# STM32H503 register map
File version: 0.3
CPU: CM33 r0p0, little endian, MPU, FPU, 4 interrupt priority bits
Registers are 32-bit, read-write, reset 0x0 unless marked. A register's access mark holds for its fields unless they carry their own. Offsets are from the block's base; [hi:lo] are bit positions; {n}, {i} and the like mark numbered series.

## GPIOA — General-purpose I/Os
Base 0x42020000
Same registers: GPIOB 0x42020400, GPIOC 0x42020800, GPIOD 0x42020C00, GPIOH 0x42021C00
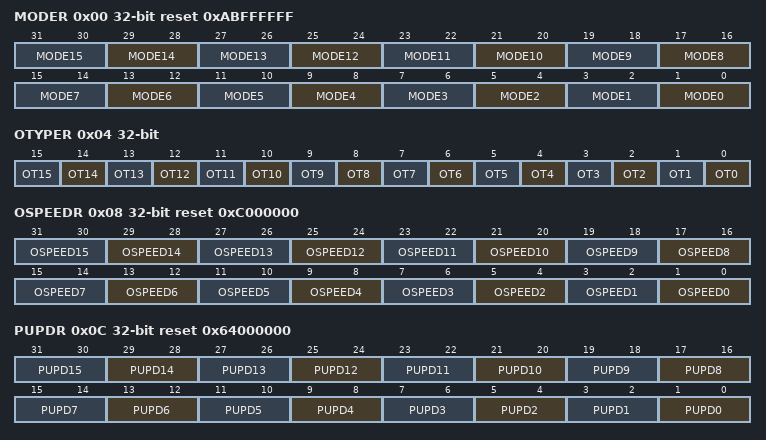
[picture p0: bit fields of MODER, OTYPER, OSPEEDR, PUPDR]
0x00 MODER reset 0xABFFFFFF — GPIO port mode register
  [2n+1:2n] MODE{n} (n=0..15) — Port x configuration I/O pin y (y = 15 to 0) These bits are written by software to configure the I/O mode. Note: The bitfield is reserved and must be kept to reset value when the corresponding I/O is not available on the selected package.
0x04 OTYPER — GPIO port output type register
  [n] OT{n} (n=0..15) — Port x configuration I/O pin y (y = 15 to 0) These bits are written by software to configure the I/O output type. Note: The bit is reserved and must be kept to reset value when the corresponding I/O is not available on the selected package.
0x08 OSPEEDR reset 0xC000000 — GPIO port output speed register
  [2n+1:2n] OSPEED{n} (n=0..15) — Port x configuration I/O pin y (y = 15 to 0) These bits are written by software to configure the I/O output speed. Note: Refer to the device datasheet for the frequency specifications and the power supply and load conditions for each speed. The bitfield is reserved and must be kept to reset value when the corresponding I/O is not available on the selected package.
0x0C PUPDR reset 0x64000000 — GPIO port pull-up/pull-down register
  [2n+1:2n] PUPD{n} (n=0..15) — Port x configuration I/O pin y (y = 15 to 0) These bits are written by software to configure the I/O pull-up or pull-down Note: The bitfield is reserved and must be kept to reset value when the corresponding I/O is not available on the selected package.
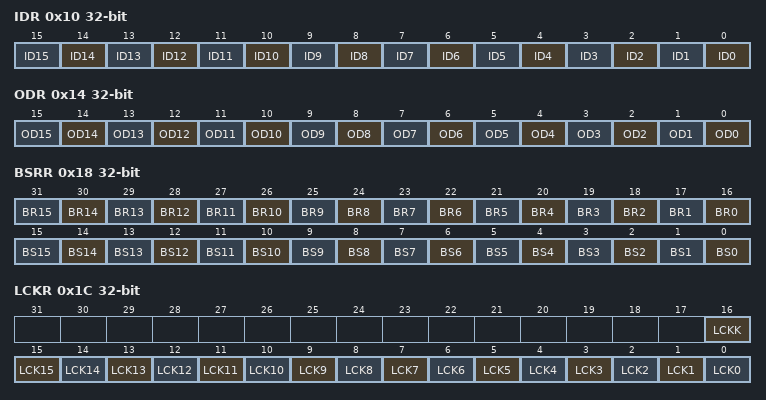
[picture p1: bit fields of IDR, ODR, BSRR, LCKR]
0x10 IDR ro (reset mask 0xFFFF0000) — GPIO port input data register
  [n] ID{n} (n=0..15) — Port x input data I/O pin y (y = 15 to 0) These bits are read-only. They contain the input value of the corresponding I/O port. Note: The bit is reserved and must be kept to reset value when the corresponding I/O is not available on the selected package.
0x14 ODR — GPIO port output data register
  [n] OD{n} (n=0..15) — Port output data I/O pin y (y = 15 to 0) These bits can be read and written by software. Note: For atomic bit set/reset, the OD bits can be individually set and/or reset by writing to the GPIOx_BSRR or GPIOx_BRR registers (x = A to D and H). The bit is reserved and must be kept to reset value when the corresponding I/O is not available on the selected package.
0x18 BSRR wo — GPIO port bit set/reset register
  [n+16] BR{n} (n=0..15) — Port x reset I/O pin y (y = 15 to 0) These bits are write-only. A read to these bits returns the value 0x0000. Note: If both BSy and BRy are set, BSy has priority. The bit is reserved and must be kept to reset value when the corresponding I/O is not available on the selected package.
  [n] BS{n} (n=0..15) — Port x set I/O pin y (y = 15 to 0) These bits are write-only. A read to these bits returns the value 0x0000. Note: The bit is reserved and must be kept to reset value when the corresponding I/O is not available on the selected package.
0x1C LCKR — GPIO port configuration lock register
  [16] LCKK — Lock key This bit can be read any time. It can only be modified using the lock key write sequence. - LOCK key write sequence: WR LCKR[16] = 1 + LCKR[15:0] WR LCKR[16] = 0 + LCKR[15:0] WR LCKR[16] = 1 + LCKR[15:0] - LOCK key read RD LCKR[16] = 1 (this read operation is optional but it confirms that the lock is active) Note: During the LOCK key write sequence, the value of LCK[15:0] must not change. Any error in the lock sequence aborts the LOCK. After the first LOCK sequence on any bit of the port, any read access on the LCKK bit returns 1 until the next MCU reset or peripheral reset.
  [n] LCK{n} (n=0..15) — Port x lock I/O pin y (y = 15 to 0) These bits are read/write but can only be written when the LCKK bit is 0 Note: The bit is reserved and must be kept to reset value when the corresponding I/O is not available on the selected package.
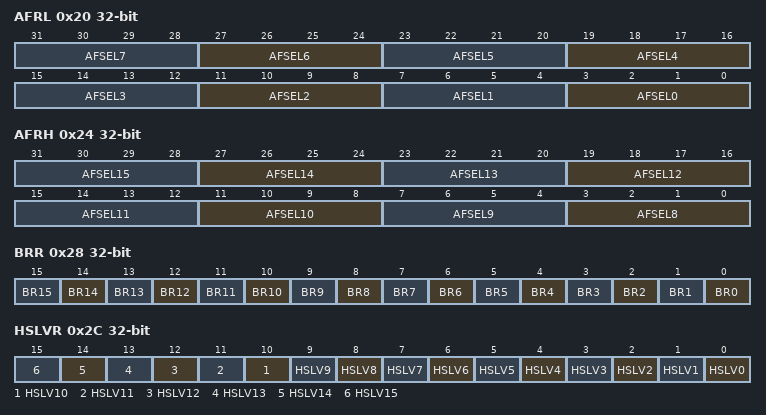
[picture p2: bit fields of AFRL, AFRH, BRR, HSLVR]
0x20 AFRL — GPIO alternate function low register
  [4n+3:4n] AFSEL{n} (n=0..7) — Alternate function selection for port x I/O pin y (y = 7 to 0) These bits are written by software to configure alternate function I/Os. Note: The bitfield is reserved and must be kept to reset value when the corresponding I/O is not available on the selected package.
0x24 AFRH — GPIO alternate function high register
  [4n-29:4n-32] AFSEL{n} (n=8..15) — Alternate function selection for port x I/O pin y (y = 15 to 8) These bits are written by software to configure alternate function I/Os. Note: The bitfield is reserved and must be kept to reset value when the corresponding I/O is not available on the selected package.
0x28 BRR wo — GPIO port bit reset register
  [n] BR{n} (n=0..15) — Port x reset IO pin y (y = 15 to 0) These bits are write-only. A read to these bits returns the value 0x0000. Note: The bit is reserved and must be kept to reset value when the corresponding I/O is not available on the selected package.
0x2C HSLVR — GPIO high-speed low-voltage register
  [n] HSLV{n} (n=0..15) — Port x high-speed low-voltage configuration (y = 15 to 0) These bits are written by software to optimize the I/O speed when the I/O supply is low. Each bit is active only if the corresponding IO_VDD_HSLV/IO_VDDIO2_HSLV user option bit is set. It must be used only if the I/O supply voltage is below 2.7 V. Setting these bits when the I/O supply (VDD or VDDIO2) is higher than 2.7 V may be destructive. Note: Not all I/Os support the HSLV mode. Refer to the I/O structure in the corresponding datasheet for the list of I/Os supporting this feature. Other I/Os HSLV configuration must be kept at reset value. The bit is reserved and must be kept to reset value when the corresponding I/O is not available on the selected package.
